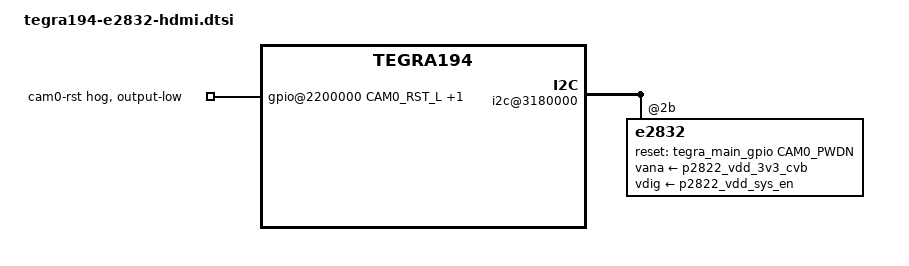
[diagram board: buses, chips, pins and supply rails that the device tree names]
/*
 * Copyright (c) 2017-2020, NVIDIA CORPORATION.  All rights reserved.
 *
 * This program is free software; you can redistribute it and/or modify
 * it under the terms of the GNU General Public License as published by
 * the Free Software Foundation; either version 2 of the License, or
 * (at your option) any later version.
 *
 * This program is distributed in the hope that it will be useful, but WITHOUT
 * ANY WARRANTY; without even the implied warranty of MERCHANTABILITY or
 * FITNESS FOR A PARTICULAR PURPOSE.  See the GNU General Public License for
 * more details.
 *
 * You should have received a copy of the GNU General Public License
 * along with this program.  If not, see <http://www.gnu.org/licenses/>.
 */
#include <t19x-common-modules/tegra194-camera-e2832.dtsi>
#include "dt-bindings/clock/tegra194-clock.h"

#define CAM0_RST_L	TEGRA194_MAIN_GPIO(H, 3)
#define CAM0_PWDN	TEGRA194_MAIN_GPIO(H, 6)
#define CAMERA_I2C_MUX_BUS(x) (0x1E + x)

/* camera control gpio definitions */

/ {
	gpio@2200000 {
		camera-control-output-low {
			gpio-hog;
			output-low;
			gpios = <CAM0_RST_L 0 CAM0_PWDN 0>;
			label = "cam0-rst", "cam0-pwdn";
		};
	};

	i2c@3180000 {
		e2832@2b {
			/* Define any required hw resources needed by driver */
			/* ie. clocks, io pins, power sources */
			clocks = <&bpmp_clks TEGRA194_CLK_EXTPERIPH1>,
				<&bpmp_clks TEGRA194_CLK_EXTPERIPH1>;
			clock-names = "extperiph1", "pllp_grtba";
			mclk = "extperiph1";
			reset-gpios = <&tegra_main_gpio CAM0_PWDN GPIO_ACTIVE_HIGH>;
			vana-supply = <&p2822_vdd_3v3_cvb>;
			vdig-supply = <&p2822_vdd_sys_en>;
		};
	};
};
